# N32G451 register map
Vendor: NSING TECHNOLOGIES PTE. LTD.; File version: 1.0
Registers are 32-bit, read-write, reset 0x0 unless marked. A register's access mark holds for its fields unless they carry their own. Offsets are from the block's base; [hi:lo] are bit positions; {n}, {i} and the like mark numbered series; 'fields as' and 'values as' point back to an identical list.

## IWDG — Independent watchdog
Base 0x40003000
0x00 IWDG_KEY
  [15:0] KEYV
0x04 IWDG_PREDIV
  [2:0] PD
0x08 IWDG_RELV reset 0xFFF
  [11:0] REL
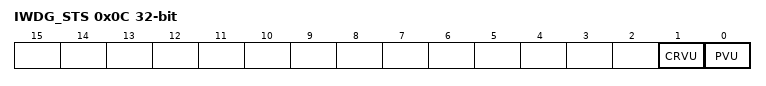
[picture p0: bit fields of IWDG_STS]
0x0C IWDG_STS
  [1] CRVU, [0] PVU

## PWR — Power control
Base 0x40007000
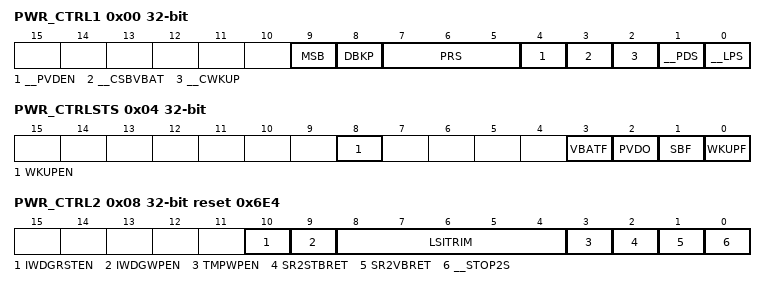
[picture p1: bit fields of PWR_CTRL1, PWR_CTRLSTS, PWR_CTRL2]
0x00 PWR_CTRL1
  [9] MSB, [8] DBKP, [7:5] PRS, [4] __PVDEN, [3] __CSBVBAT, [2] __CWKUP, [1] __PDS, [0] __LPS
0x04 PWR_CTRLSTS
  [8] WKUPEN, [3] VBATF, [2] PVDO, [1] SBF, [0] WKUPF
0x08 PWR_CTRL2 reset 0x6E4
  [10] IWDGRSTEN, [9] IWDGWPEN, [8:4] LSITRIM, [3] TMPWPEN, [2] SR2STBRET, [1] SR2VBRET, [0] __STOP2S
0x0C PWR_CTRL3
  [0] EXMODE

## RCC — Reset and clock control
Base 0x40021000
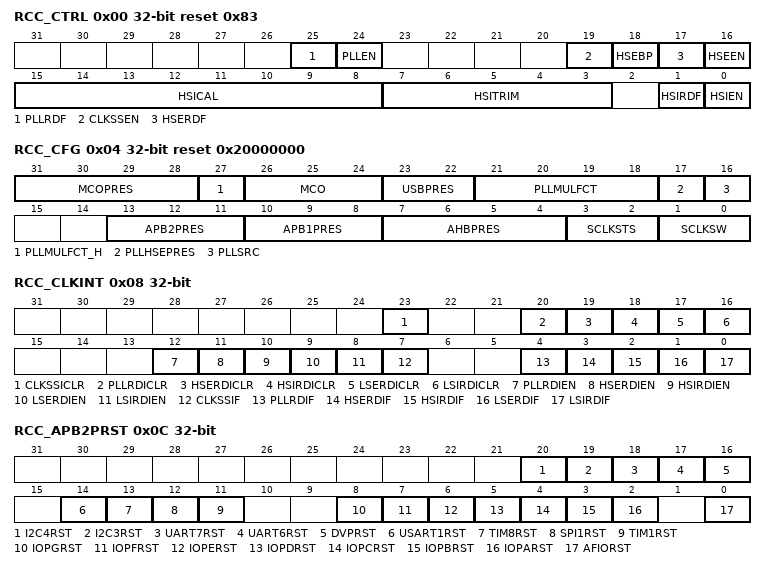
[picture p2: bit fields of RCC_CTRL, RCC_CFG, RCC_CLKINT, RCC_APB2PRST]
0x00 RCC_CTRL reset 0x83
  [25] PLLRDF, [24] PLLEN, [19] CLKSSEN, [18] HSEBP, [17] HSERDF, [16] HSEEN, [15:8] HSICAL, [7:3] HSITRIM, [1] HSIRDF, [0] HSIEN
0x04 RCC_CFG reset 0x20000000
  [31:28] MCOPRES, [27] PLLMULFCT_H, [26:24] MCO, [23:22] USBPRES, [21:18] PLLMULFCT, [17] PLLHSEPRES, [16] PLLSRC, [13:11] APB2PRES, [10:8] APB1PRES, [7:4] AHBPRES, [3:2] SCLKSTS, [1:0] SCLKSW
0x08 RCC_CLKINT
  [23] CLKSSICLR, [20] PLLRDICLR, [19] HSERDICLR, [18] HSIRDICLR, [17] LSERDICLR, [16] LSIRDICLR, [12] PLLRDIEN, [11] HSERDIEN, [10] HSIRDIEN, [9] LSERDIEN, [8] LSIRDIEN, [7] CLKSSIF, [4] PLLRDIF, [3] HSERDIF, [2] HSIRDIF, [1] LSERDIF, [0] LSIRDIF
0x0C RCC_APB2PRST
  [20] I2C4RST, [19] I2C3RST, [18] UART7RST, [17] UART6RST, [16] DVPRST, [14] USART1RST, [13] TIM8RST, [12] SPI1RST, [11] TIM1RST, [8] IOPGRST, [7] IOPFRST, [6] IOPERST, [5] IOPDRST, [4] IOPCRST, [3] IOPBRST, [2] IOPARST, [0] AFIORST
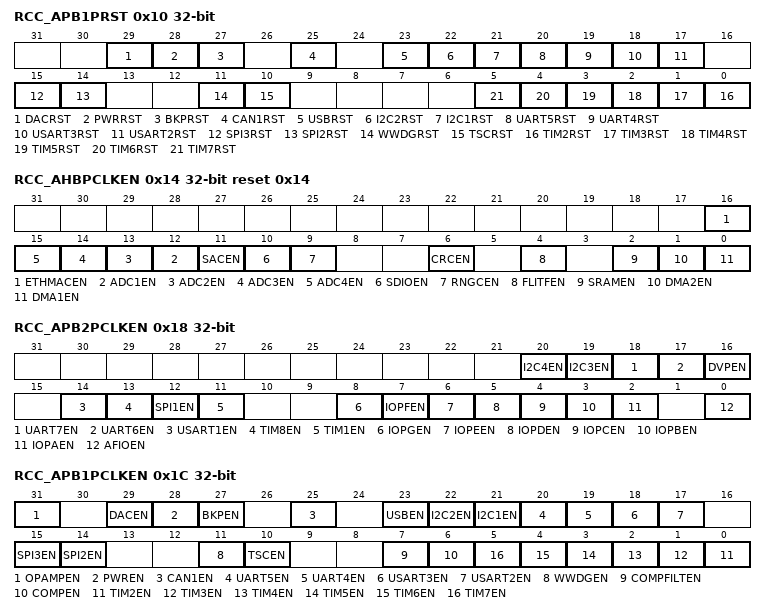
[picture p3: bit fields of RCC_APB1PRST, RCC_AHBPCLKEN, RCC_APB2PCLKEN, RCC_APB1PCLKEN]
0x10 RCC_APB1PRST
  [29] DACRST, [28] PWRRST, [27] BKPRST, [25] CAN1RST, [23] USBRST, [22] I2C2RST, [21] I2C1RST, [20] UART5RST, [19] UART4RST, [18] USART3RST, [17] USART2RST, [15] SPI3RST, [14] SPI2RST, [11] WWDGRST, [10] TSCRST, [n-2] TIM{n}RST (n=2..7)
0x14 RCC_AHBPCLKEN reset 0x14
  [16] ETHMACEN, [n+11] ADC{n}EN (n=1..4), [11] SACEN, [10] SDIOEN, [9] RNGCEN, [6] CRCEN, [4] FLITFEN, [2] SRAMEN, [1] DMA2EN, [0] DMA1EN
0x18 RCC_APB2PCLKEN
  [20] I2C4EN, [19] I2C3EN, [18] UART7EN, [17] UART6EN, [16] DVPEN, [14] USART1EN, [13] TIM8EN, [12] SPI1EN, [11] TIM1EN, [8] IOPGEN, [7] IOPFEN, [6] IOPEEN, [5] IOPDEN, [4] IOPCEN, [3] IOPBEN, [2] IOPAEN, [0] AFIOEN
0x1C RCC_APB1PCLKEN
  [31] OPAMPEN, [29] DACEN, [28] PWREN, [27] BKPEN, [25] CAN1EN, [23] USBEN, [22] I2C2EN, [21] I2C1EN, [20] UART5EN, [19] UART4EN, [18] USART3EN, [17] USART2EN, [15] SPI3EN, [14] SPI2EN, [11] WWDGEN, [10] TSCEN, [7] COMPFILTEN, [6] COMPEN, [n-2] TIM{n}EN (n=2..7)
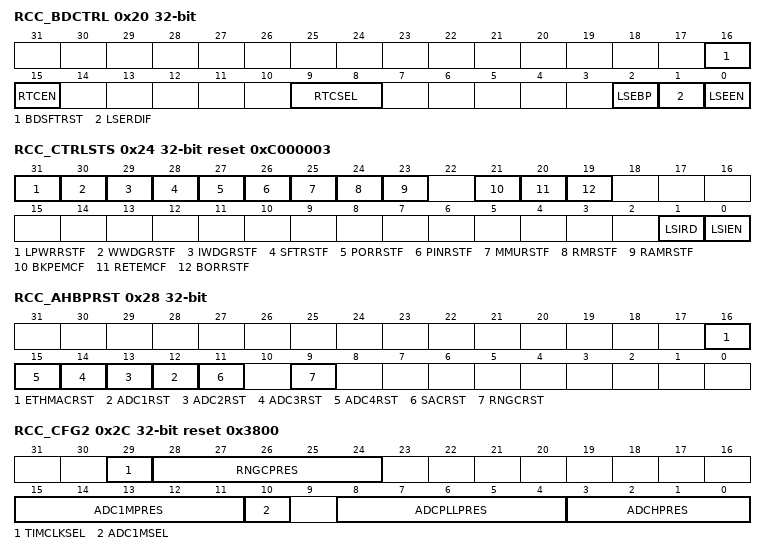
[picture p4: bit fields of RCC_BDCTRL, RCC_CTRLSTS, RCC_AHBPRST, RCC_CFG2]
0x20 RCC_BDCTRL
  [16] BDSFTRST, [15] RTCEN, [9:8] RTCSEL, [2] LSEBP, [1] LSERDIF, [0] LSEEN
0x24 RCC_CTRLSTS reset 0xC000003
  [31] LPWRRSTF, [30] WWDGRSTF, [29] IWDGRSTF, [28] SFTRSTF, [27] PORRSTF, [26] PINRSTF, [25] MMURSTF, [24] RMRSTF, [23] RAMRSTF, [21] BKPEMCF, [20] RETEMCF, [19] BORRSTF, [1] LSIRD, [0] LSIEN
0x28 RCC_AHBPRST
  [16] ETHMACRST, [n+11] ADC{n}RST (n=1..4), [11] SACRST, [9] RNGCRST
0x2C RCC_CFG2 reset 0x3800
  [29] TIMCLKSEL, [28:24] RNGCPRES, [15:11] ADC1MPRES, [10] ADC1MSEL, [8:4] ADCPLLPRES, [3:0] ADCHPRES
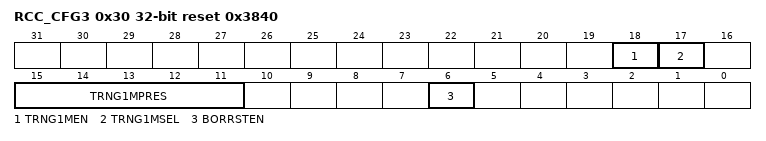
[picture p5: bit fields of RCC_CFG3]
0x30 RCC_CFG3 reset 0x3840
  [18] TRNG1MEN, [17] TRNG1MSEL, [15:11] TRNG1MPRES, [6] BORRSTEN

## RTC — Real time clock
Base 0x40002800
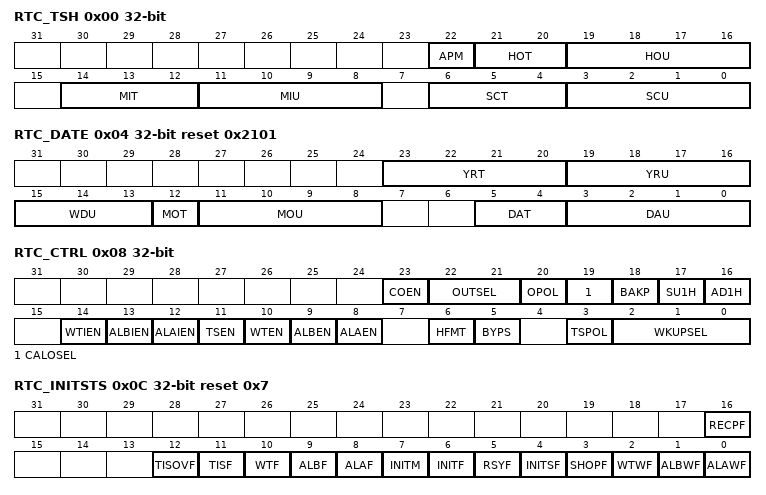
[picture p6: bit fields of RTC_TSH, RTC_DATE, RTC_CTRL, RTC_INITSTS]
0x00 RTC_TSH
  [22] APM, [21:20] HOT, [19:16] HOU, [14:12] MIT, [11:8] MIU, [6:4] SCT, [3:0] SCU
0x04 RTC_DATE reset 0x2101
  [23:20] YRT, [19:16] YRU, [15:13] WDU, [12] MOT, [11:8] MOU, [5:4] DAT, [3:0] DAU
0x08 RTC_CTRL (reset mask 0xFF7F67)
  [23] COEN, [22:21] OUTSEL, [20] OPOL, [19] CALOSEL, [18] BAKP, [17] SU1H, [16] AD1H, [14] WTIEN, [13] ALBIEN, [12] ALAIEN, [11] TSEN, [10] WTEN, [9] ALBEN, [8] ALAEN, [6] HFMT, [5] BYPS, [3] TSPOL, [2:0] WKUPSEL
0x0C RTC_INITSTS reset 0x7
  [16] RECPF, [12] TISOVF, [11] TISF, [10] WTF, [9] ALBF, [8] ALAF, [7] INITM, [6] INITF, [5] RSYF, [4] INITSF, [3] SHOPF, [2] WTWF, [1] ALBWF, [0] ALAWF
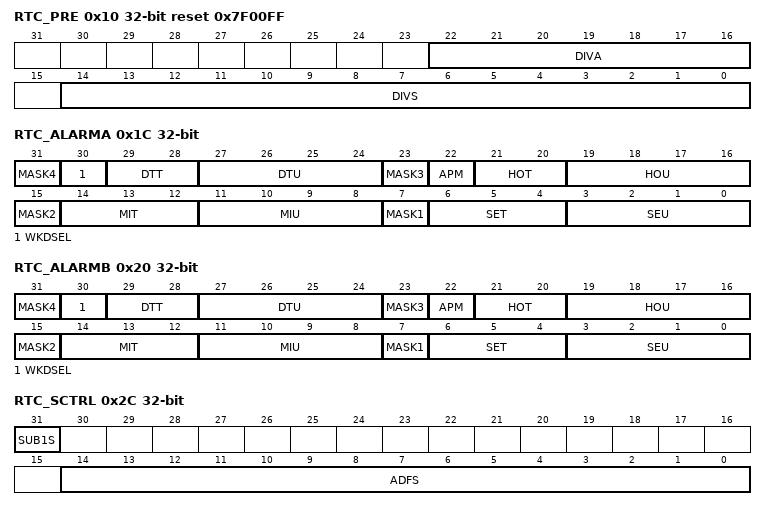
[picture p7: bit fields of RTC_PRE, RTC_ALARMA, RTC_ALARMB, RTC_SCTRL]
0x10 RTC_PRE reset 0x7F00FF
  [22:16] DIVA, [14:0] DIVS
0x14 RTC_WKUPT reset 0xFFFF
  [15:0] WKUPT
0x1C RTC_ALARMA
  [8n-1] MASK{n} (n=1..4), [30] WKDSEL, [29:28] DTT, [27:24] DTU, [22] APM, [21:20] HOT, [19:16] HOU, [14:12] MIT, [11:8] MIU, [6:4] SET, [3:0] SEU
0x20 RTC_ALARMB
  fields as RTC_ALARMA
0x24 RTC_WRP
  [7:0] PKEY
0x28 RTC_SUBS
  [15:0] SS
0x2C RTC_SCTRL
  [31] SUB1S, [14:0] ADFS
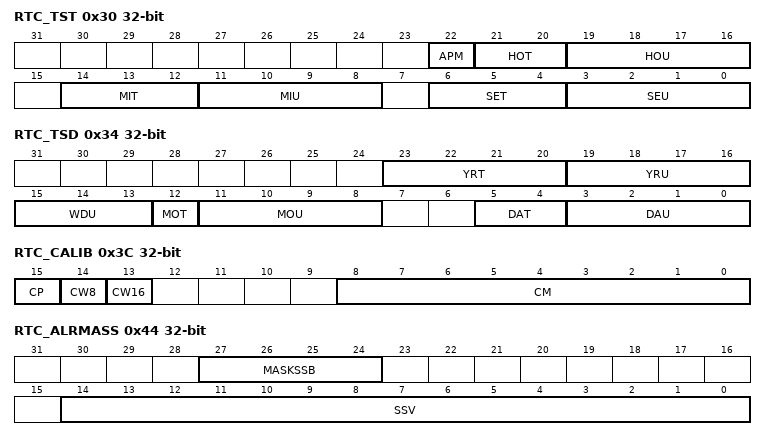
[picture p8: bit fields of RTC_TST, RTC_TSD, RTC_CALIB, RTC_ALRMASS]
0x30 RTC_TST (reset mask 0x7F)
  [22] APM, [21:20] HOT, [19:16] HOU, [14:12] MIT, [11:8] MIU, [6:4] SET, [3:0] SEU
0x34 RTC_TSD
  fields as RTC_DATE
0x38 RTC_TSSS
  [15:0] SSE
0x3C RTC_CALIB (reset mask 0xFF)
  [15] CP, [14] CW8, [13] CW16, [8:0] CM
0x44 RTC_ALRMASS
  [27:24] MASKSSB, [14:0] SSV
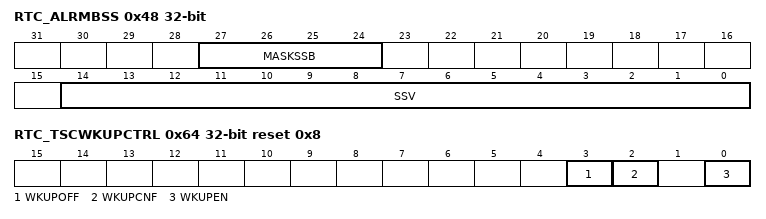
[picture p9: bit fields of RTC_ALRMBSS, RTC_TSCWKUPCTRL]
0x48 RTC_ALRMBSS
  [27:24] MASKSSB, [14:0] SSV
0x4C RTC_OPT
  [0] TYPE
0x64 RTC_TSCWKUPCTRL reset 0x8
  [3] WKUPOFF, [2] WKUPCNF, [0] WKUPEN
0x68 RTC_TSCWKUPCNT reset 0x2FE
  [13:0] CNT
